AUTOSAR XML (schema 00049)
package /Application/DltConfig
  6 x dlt log channel to process mapping:
    DltLogChannelToProcessMapping_CM_TO_CM: dlt-log-channel=CM, process=CM
    DltLogChannelToProcessMapping_EM_TO_EM: dlt-log-channel=EM, process=EM
    DltLogChannelToProcessMapping_PHM_TO_PHM: dlt-log-channel=PHM, process=PHM
    DltLogChannelToProcessMapping_SM_TO_SM: dlt-log-channel=SM, process=SM
    DltLogChannelToProcessMapping_UCM_TO_UCM: dlt-log-channel=UCM, process=UCM
    DltLogChannelToProcessMapping_VUCM_TO_VUCM: dlt-log-channel=VUCM, process=VUCM
package /Application/Executable
  6 x executable, all with category=PLATFORM_LEVEL, logging-behavior=USES-LOGGING, version=1.0.0:
    CM: reporting-behavior=REPORTS-EXECUTION-STATE
      root sw component prototype PARA: application-type=CM
    EM: reporting-behavior=DOES-NOT-REPORT-EXECUTION-STATE
      root sw component prototype PARA: application-type=EM
    PHM: reporting-behavior=REPORTS-EXECUTION-STATE
      root sw component prototype PARA: application-type=PHM
    SM: reporting-behavior=REPORTS-EXECUTION-STATE
      root sw component prototype PARA: application-type=SM
    UCM: reporting-behavior=REPORTS-EXECUTION-STATE
      root sw component prototype PARA: application-type=UCM
    VUCM: reporting-behavior=REPORTS-EXECUTION-STATE
      root sw component prototype PARA: application-type=VUCM
package /Application/Manifest
  7 x service instance to port prototype mapping:
    SM_PARA_MachineFG: port-prototype=PARA.MachineFG, service-instance=EEVP_Platform_Provider_TriggerInOut_MachineFG
    SM_PARA_UpdateRequest: port-prototype=PARA.UpdateRequest, service-instance=EEVP_Platform_Provider_UpdateRequest
    UCM_PARA_PackageManagement: port-prototype=PARA.PackageManagement, service-instance=EEVP_Platform_Provider_PackageManagement
    UCM_PARA_UpdateRequest: port-prototype=PARA.UpdateRequest, service-instance=EEVP_Platform_Consumer_UpdateRequest
    VUCM_PARA_DriverNotification: port-prototype=PARA.DriverNotification, service-instance=EEVP_Platform_Provider_VehicleDriverApplication
    VUCM_PARA_PackageManagement: port-prototype=PARA.PackageManagement, service-instance=EEVP_Platform_Consumer_PackageManagement
    VUCM_PARA_VehiclePackageManagement: port-prototype=PARA.VehiclePackageManagement, service-instance=EEVP_Platform_Provider_VehiclePackageManagement
package /Application/Process
  6 x process:
    CM: executable=CM, state-dependent-startup-config{function-group-state=[MachineFG.Startup, MachineFG.Restart, MachineFG.Shutdown, MachineFG.Verify], resource-group=DefaultResourceGroup, startup-config=CM}
      process state machine CM: type=ProcessState
    EM: executable=EM
    PHM: executable=PHM, function-cluster-affiliation=PLATFORM_HEALTH_MANAGEMENT, state-dependent-startup-config{function-group-state=[MachineFG.Startup, MachineFG.Restart, MachineFG.Shutdown, MachineFG.Verify], resource-group=DefaultResourceGroup, startup-config=PHM}
      process state machine PHM: type=ProcessState
    SM: executable=SM, function-cluster-affiliation=STATE_MANAGEMENT, state-dependent-startup-config{execution-dependencys=[CM.Running, IPCHandler.Running], function-group-state=[MachineFG.Startup, MachineFG.Restart, MachineFG.Shutdown, MachineFG.Verify], resource-group=DefaultResourceGroup, startup-config=SM}
      process state machine SM: type=ProcessState
    UCM: executable=UCM, state-dependent-startup-config{execution-dependencys=[CM.Running, SM.Running], function-group-state=[MachineFG.Startup, MachineFG.Restart, MachineFG.Shutdown, MachineFG.Verify], resource-group=DefaultResourceGroup, startup-config=UCM}
      process state machine UCM: type=ProcessState
    VUCM: executable=VUCM, state-dependent-startup-config{execution-dependency=UCM.Running, function-group-state=[MachineFG.Startup, MachineFG.Restart, MachineFG.Shutdown, MachineFG.Verify], resource-group=DefaultResourceGroup, startup-config=VUCM}
      process state machine VUCM: type=ProcessState
package /Application/StartupConfig
  startup config set EEVP_Platform_StartupConfig
    6 x startup config, all with scheduling-policy=SCHED_OTHER, scheduling-priority=0:
      CM: timeout={enter-timeout-value=2.0, exit-timeout-value=2.0}
      DefaultStartupConfig: timeout={enter-timeout-value=2.0, exit-timeout-value=2.0}
      PHM: timeout={enter-timeout-value=2.0, exit-timeout-value=2.0}
      SM: timeout={enter-timeout-value=1.0, exit-timeout-value=1.0}
      UCM: timeout={enter-timeout-value=2.0, exit-timeout-value=2.0}
      VUCM: timeout={enter-timeout-value=2.0, exit-timeout-value=2.0}
package /Application/SwComponent
  adaptive application sw component type CM
  adaptive application sw component type DM
  adaptive application sw component type EM
  adaptive application sw component type IAM
  adaptive application sw component type IDSM
  adaptive application sw component type NM
    provide port NetworkState_NetworkHandle: provided-interface=NetworkState
  adaptive application sw component type PHM
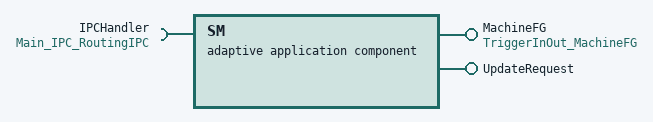
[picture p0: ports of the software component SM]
  adaptive application sw component type SM
    require port IPCHandler: required-interface=Main_IPC_RoutingIPC
    provide port MachineFG: provided-interface=TriggerInOut_MachineFG
    provide port UpdateRequest: provided-interface=UpdateRequest
  adaptive application sw component type TSM
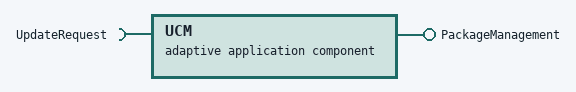
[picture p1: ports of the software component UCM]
  adaptive application sw component type UCM
    provide port PackageManagement: provided-interface=PackageManagement
    require port UpdateRequest: required-interface=UpdateRequest
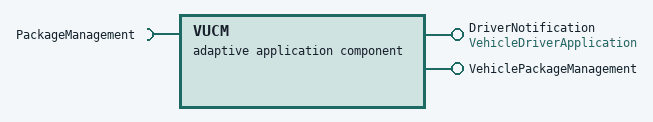
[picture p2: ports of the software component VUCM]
  adaptive application sw component type VUCM
    provide port DriverNotification: provided-interface=VehicleDriverApplication
    require port PackageManagement: required-interface=PackageManagement
    provide port VehiclePackageManagement: provided-interface=VehiclePackageManagement
